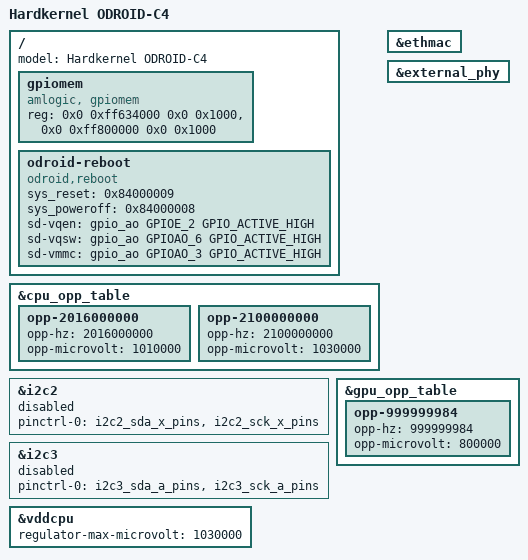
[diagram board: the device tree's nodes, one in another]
// SPDX-License-Identifier: (GPL-2.0+ OR MIT)
/*
 * Copyright (c) 2020 Dongjin Kim <tobetter@gmail.com>
 */

/dts-v1/;

#include "meson-sm1-odroid-c4.dts"

/ {
	model = "Hardkernel ODROID-C4";

	gpiomem {
		compatible = "amlogic, gpiomem";
		reg = <0x0 0xff634000 0x0 0x1000>,	/* GPIO banks */
			<0x0 0xff800000 0x0 0x1000>;	/* GPIO_AO bank */
		status = "okay";
	};

	odroid-reboot {
		compatible = "odroid,reboot";
		sys_reset = <0x84000009>;
		sys_poweroff = <0x84000008>;

		sd-vqen = <&gpio_ao GPIOE_2 GPIO_ACTIVE_HIGH>;
		sd-vqsw = <&gpio_ao GPIOAO_6 GPIO_ACTIVE_HIGH>;
		sd-vmmc = <&gpio_ao GPIOAO_3 GPIO_ACTIVE_HIGH>;
	};
};

&cpu_opp_table {
	/delete-node/ opp-100000000;
	/delete-node/ opp-250000000;
	/delete-node/ opp-500000000;
	/delete-node/ opp-667000000;

	opp-2016000000 {
		opp-hz = /bits/ 64 <2016000000>;
		opp-microvolt = <1010000>;
	};
	opp-2100000000 {
		opp-hz = /bits/ 64 <2100000000>;
		opp-microvolt = <1030000>;
	};
};

&ethmac {
	/delete-property/	resets;
	/delete-property/	reset-names;
};

&external_phy {
	/delete-property/	interrupts;
	/delete-property/	interrupts-parent;
};

&i2c2 {
	status = "disabled";
	pinctrl-names = "default";
	pinctrl-0 = <&i2c2_sda_x_pins>, <&i2c2_sck_x_pins>;
};

&i2c3 {
	status = "disabled";
	pinctrl-names = "default";
	pinctrl-0 = <&i2c3_sda_a_pins>, <&i2c3_sck_a_pins>;
};

&gpu_opp_table {
	opp-999999984 {
		opp-hz = /bits/ 64 <999999984>;
		opp-microvolt = <800000>;
	};
};

&vddcpu {
	regulator-max-microvolt = <1030000>;
};
